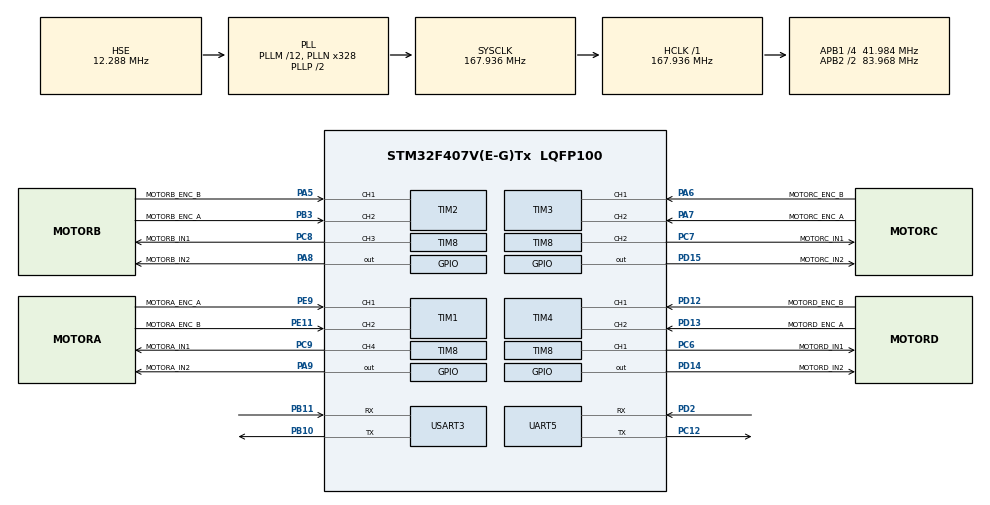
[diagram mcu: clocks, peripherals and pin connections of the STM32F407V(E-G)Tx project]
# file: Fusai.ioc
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Dma.Request0=UART5_RX
Dma.Request1=USART3_RX
Dma.UART5_RX.0.Direction=DMA_PERIPH_TO_MEMORY
Dma.UART5_RX.0.FIFOMode=DMA_FIFOMODE_DISABLE
Dma.UART5_RX.0.Instance=DMA1_Stream0
Dma.UART5_RX.0.MemDataAlignment=DMA_MDATAALIGN_BYTE
Dma.UART5_RX.0.MemInc=DMA_MINC_ENABLE
Dma.UART5_RX.0.Mode=DMA_CIRCULAR
Dma.UART5_RX.0.PeriphDataAlignment=DMA_PDATAALIGN_BYTE
Dma.UART5_RX.0.PeriphInc=DMA_PINC_DISABLE
Dma.UART5_RX.0.Priority=DMA_PRIORITY_MEDIUM
Dma.USART3_RX.1.Direction=DMA_PERIPH_TO_MEMORY
Dma.USART3_RX.1.FIFOMode=DMA_FIFOMODE_DISABLE
Dma.USART3_RX.1.Instance=DMA1_Stream1
Dma.USART3_RX.1.MemDataAlignment=DMA_MDATAALIGN_BYTE
Dma.USART3_RX.1.MemInc=DMA_MINC_ENABLE
Dma.USART3_RX.1.Mode=DMA_CIRCULAR
Dma.USART3_RX.1.PeriphDataAlignment=DMA_PDATAALIGN_BYTE
Dma.USART3_RX.1.PeriphInc=DMA_PINC_DISABLE
Dma.USART3_RX.1.Priority=DMA_PRIORITY_MEDIUM
FREERTOS.Tasks01=defaultTask,24,256,StartDefaultTask,As weak,NULL,Dynamic,NULL,NULL
FREERTOS.configCHECK_FOR_STACK_OVERFLOW=2
FREERTOS.configENABLE_FPU=1
FREERTOS.configMINIMAL_STACK_SIZE=256
Mcu.Family=STM32F4
Mcu.Name=STM32F407V(E-G)Tx
Mcu.Package=LQFP100
NVIC.DMA1_Stream0_IRQn=true\:5\:0\:false\:false\:true\:true\:false\:true\:true
NVIC.DMA1_Stream1_IRQn=true\:5\:0\:false\:false\:true\:true\:false\:true\:true
NVIC.PriorityGroup=NVIC_PRIORITYGROUP_4
NVIC.TIM1_UP_TIM10_IRQn=true\:5\:0\:true\:false\:true\:true\:true\:true\:true
NVIC.TIM8_TRG_COM_TIM14_IRQn=true\:15\:0\:false\:false\:true\:false\:false\:true\:true
NVIC.TimeBase=TIM8_TRG_COM_TIM14_IRQn
NVIC.TimeBaseIP=TIM14
NVIC.UART5_IRQn=true\:5\:0\:false\:false\:true\:true\:true\:true\:true
NVIC.USART3_IRQn=true\:5\:0\:false\:false\:true\:true\:true\:true\:true
PA13.Mode=Serial_Wire
PA13.Signal=SYS_JTMS-SWDIO
PA14.Mode=Serial_Wire
PA14.Signal=SYS_JTCK-SWCLK
PA5.GPIO_Label=MOTORB_ENC_B
PA5.GPIO_Speed=GPIO_SPEED_FREQ_HIGH
PA5.Signal=S_TIM2_CH1_ETR
PA6.GPIO_Label=MOTORC_ENC_B
PA6.GPIO_Speed=GPIO_SPEED_FREQ_HIGH
PA6.Signal=S_TIM3_CH1
PA7.GPIO_Label=MOTORC_ENC_A
PA7.GPIO_Speed=GPIO_SPEED_FREQ_HIGH
PA7.Signal=S_TIM3_CH2
PA8.GPIO_Label=MOTORB_IN2
PA8.GPIO_Speed=GPIO_SPEED_FREQ_HIGH
PA8.Signal=GPIO_Output
PA9.GPIO_Label=MOTORA_IN2
PA9.GPIO_Speed=GPIO_SPEED_FREQ_HIGH
PA9.Signal=GPIO_Output
PB10.Mode=Asynchronous
PB10.Signal=USART3_TX
PB11.Mode=Asynchronous
PB11.Signal=USART3_RX
PB3.GPIO_Label=MOTORB_ENC_A
PB3.GPIO_Speed=GPIO_SPEED_FREQ_HIGH
PB3.Signal=S_TIM2_CH2
PC12.Mode=Asynchronous
PC12.Signal=UART5_TX
PC6.GPIO_Label=MOTORD_IN1
PC6.GPIO_Speed=GPIO_SPEED_FREQ_HIGH
PC6.Signal=S_TIM8_CH1
PC7.GPIO_Label=MOTORC_IN1
PC7.GPIO_Speed=GPIO_SPEED_FREQ_HIGH
PC7.Signal=S_TIM8_CH2
PC8.GPIO_Label=MOTORB_IN1
PC8.GPIO_Speed=GPIO_SPEED_FREQ_HIGH
PC8.Signal=S_TIM8_CH3
PC9.GPIO_Label=MOTORA_IN1
PC9.GPIO_Speed=GPIO_SPEED_FREQ_HIGH
PC9.Signal=S_TIM8_CH4
PD12.GPIO_Label=MOTORD_ENC_B
PD12.GPIO_Speed=GPIO_SPEED_FREQ_HIGH
PD12.Signal=S_TIM4_CH1
PD13.GPIO_Label=MOTORD_ENC_A
PD13.GPIO_Speed=GPIO_SPEED_FREQ_HIGH
PD13.Signal=S_TIM4_CH2
PD14.GPIO_Label=MOTORD_IN2
PD14.GPIO_Speed=GPIO_SPEED_FREQ_HIGH
PD14.Signal=GPIO_Output
PD15.GPIO_Label=MOTORC_IN2
PD15.GPIO_Speed=GPIO_SPEED_FREQ_HIGH
PD15.Signal=GPIO_Output
PD2.Mode=Asynchronous
PD2.Signal=UART5_RX
PE11.GPIO_Label=MOTORA_ENC_B
PE11.GPIO_Speed=GPIO_SPEED_FREQ_HIGH
PE11.Signal=S_TIM1_CH2
PE9.GPIO_Label=MOTORA_ENC_A
PE9.GPIO_Speed=GPIO_SPEED_FREQ_HIGH
PE9.Signal=S_TIM1_CH1
PH0-OSC_IN.Mode=HSE-External-Oscillator
PH0-OSC_IN.Signal=RCC_OSC_IN
PH1-OSC_OUT.Mode=HSE-External-Oscillator
PH1-OSC_OUT.Signal=RCC_OSC_OUT
ProjectManager.HeapSize=0x200
ProjectManager.StackSize=0x400
ProjectManager.TargetToolchain=CMake
RCC.48MHZClocksFreq_Value=83968000
RCC.AHBFreq_Value=167936000
RCC.APB1CLKDivider=RCC_HCLK_DIV4
RCC.APB1Freq_Value=41984000
RCC.APB1TimFreq_Value=83968000
RCC.APB2CLKDivider=RCC_HCLK_DIV2
RCC.APB2Freq_Value=83968000
RCC.APB2TimFreq_Value=167936000
RCC.CortexFreq_Value=167936000
RCC.HCLKFreq_Value=167936000
RCC.HSE_VALUE=12288000
RCC.HSI_VALUE=16000000
RCC.LSE_VALUE=32768
RCC.PLLM=12
RCC.PLLN=328
RCC.PLLSourceVirtual=RCC_PLLSOURCE_HSE
RCC.SYSCLKFreq_VALUE=167936000
RCC.SYSCLKSource=RCC_SYSCLKSOURCE_PLLCLK
RCC.VCOOutputFreq_Value=335872000
SH.S_TIM1_CH1.0=TIM1_CH1,Encoder_Interface
SH.S_TIM1_CH2.0=TIM1_CH2,Encoder_Interface
SH.S_TIM2_CH1_ETR.0=TIM2_CH1,Encoder_Interface
SH.S_TIM2_CH2.0=TIM2_CH2,Encoder_Interface
SH.S_TIM3_CH1.0=TIM3_CH1,Encoder_Interface
SH.S_TIM3_CH2.0=TIM3_CH2,Encoder_Interface
SH.S_TIM4_CH1.0=TIM4_CH1,Encoder_Interface
SH.S_TIM4_CH2.0=TIM4_CH2,Encoder_Interface
SH.S_TIM8_CH1.0=TIM8_CH1,PWM Generation1 CH1
SH.S_TIM8_CH2.0=TIM8_CH2,PWM Generation2 CH2
SH.S_TIM8_CH3.0=TIM8_CH3,PWM Generation3 CH3
SH.S_TIM8_CH4.0=TIM8_CH4,PWM Generation4 CH4
TIM1.EncoderMode=TIM_ENCODERMODE_TI12
TIM1.IC1Filter=2
TIM1.IC2Filter=2
TIM10.Period=20000-1
TIM10.Prescaler=84-1
TIM2.EncoderMode=TIM_ENCODERMODE_TI12
TIM2.IC1Filter=2
TIM2.IC2Filter=2
TIM3.EncoderMode=TIM_ENCODERMODE_TI12
TIM3.IC1Filter=2
TIM3.IC2Filter=2
TIM4.EncoderMode=TIM_ENCODERMODE_TI12
TIM4.IC1Filter=2
TIM4.IC2Filter=2
TIM8.AutoReloadPreload=TIM_AUTORELOAD_PRELOAD_ENABLE
TIM8.Channel-PWM\ Generation1\ CH1=TIM_CHANNEL_1
TIM8.Channel-PWM\ Generation2\ CH2=TIM_CHANNEL_2
TIM8.Channel-PWM\ Generation3\ CH3=TIM_CHANNEL_3
TIM8.Channel-PWM\ Generation4\ CH4=TIM_CHANNEL_4
TIM8.Period=8400-1
TIM8.Prescaler=0
UART5.VirtualMode=Asynchronous
USART3.VirtualMode=VM_ASYNC
VP_FREERTOS_VS_CMSIS_V2.Mode=CMSIS_V2
VP_SYS_VS_tim14.Mode=TIM14
VP_TIM10_VS_ClockSourceINT.Mode=Enable_Timer
VP_TIM8_VS_ClockSourceINT.Mode=Internal
board=custom

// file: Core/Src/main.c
/* USER CODE BEGIN Header */
/**
 ******************************************************************************
 * @file           : main.c
 * @brief          : Main program body
 ******************************************************************************
 * @attention
 *
 * Copyright (c) 2026 STMicroelectronics.
 * All rights reserved.
 *
 * This software is licensed under terms that can be found in the LICENSE file
 * in the root directory of this software component.
 * If no LICENSE file comes with this software, it is provided AS-IS.
 *
 ******************************************************************************
 */
/* USER CODE END Header */
#include "main.h"
#include "cmsis_os.h"

/* USER CODE BEGIN Includes */
#include "motor.h"
/* USER CODE END Includes */

TIM_HandleTypeDef htim1;
TIM_HandleTypeDef htim2;
TIM_HandleTypeDef htim3;
TIM_HandleTypeDef htim4;
TIM_HandleTypeDef htim8;
TIM_HandleTypeDef htim10;

UART_HandleTypeDef huart5;
UART_HandleTypeDef huart3;
DMA_HandleTypeDef hdma_uart5_rx;
DMA_HandleTypeDef hdma_usart3_rx;

/* Definitions for defaultTask */
osThreadId_t defaultTaskHandle;
const osThreadAttr_t defaultTask_attributes = {
  .name = "defaultTask",
  .stack_size = 256 * 4,
  .priority = (osPriority_t) osPriorityNormal,
};

void SystemClock_Config(void);
static void MX_GPIO_Init(void);
static void MX_DMA_Init(void);
static void MX_TIM1_Init(void);
static void MX_TIM2_Init(void);
static void MX_TIM3_Init(void);
static void MX_TIM4_Init(void);
static void MX_TIM8_Init(void);
static void MX_TIM10_Init(void);
static void MX_UART5_Init(void);
static void MX_USART3_UART_Init(void);
void StartDefaultTask(void *argument);

int main(void)
{

  /* MCU Configuration--------------------------------------------------------*/

  /* Reset of all peripherals, Initializes the Flash interface and the Systick. */
  HAL_Init();

  /* Configure the system clock */
  SystemClock_Config();

  /* Initialize all configured peripherals */
  MX_GPIO_Init();
  MX_DMA_Init();
  MX_TIM1_Init();
  MX_TIM2_Init();
  MX_TIM3_Init();
  MX_TIM4_Init();
  MX_TIM8_Init();
  MX_TIM10_Init();
  MX_UART5_Init();
  MX_USART3_UART_Init();

  /* Init scheduler */
  osKernelInitialize();

  /* Create the thread(s) */
  /* creation of defaultTask */
  defaultTaskHandle = osThreadNew(StartDefaultTask, NULL, &defaultTask_attributes);

  /* Start scheduler */
  osKernelStart();

  /* We should never get here as control is now taken by the scheduler */

  /* Infinite loop */
	while (1)
	{

	}
}

void SystemClock_Config(void)
{
  RCC_OscInitTypeDef RCC_OscInitStruct = {0};
  RCC_ClkInitTypeDef RCC_ClkInitStruct = {0};

  /** Configure the main internal regulator output voltage
  */
  __HAL_RCC_PWR_CLK_ENABLE();
  __HAL_PWR_VOLTAGESCALING_CONFIG(PWR_REGULATOR_VOLTAGE_SCALE1);

  /** Initializes the RCC Oscillators according to the specified parameters
  * in the RCC_OscInitTypeDef structure.
  */
  RCC_OscInitStruct.OscillatorType = RCC_OSCILLATORTYPE_HSE;
  RCC_OscInitStruct.HSEState = RCC_HSE_ON;
  RCC_OscInitStruct.PLL.PLLState = RCC_PLL_ON;
  RCC_OscInitStruct.PLL.PLLSource = RCC_PLLSOURCE_HSE;
  RCC_OscInitStruct.PLL.PLLM = 12;
  RCC_OscInitStruct.PLL.PLLN = 328;
  RCC_OscInitStruct.PLL.PLLP = RCC_PLLP_DIV2;
  RCC_OscInitStruct.PLL.PLLQ = 4;
  if (HAL_RCC_OscConfig(&RCC_OscInitStruct) != HAL_OK)
  {
    Error_Handler();
  }

  /** Initializes the CPU, AHB and APB buses clocks
  */
  RCC_ClkInitStruct.ClockType = RCC_CLOCKTYPE_HCLK|RCC_CLOCKTYPE_SYSCLK
                              |RCC_CLOCKTYPE_PCLK1|RCC_CLOCKTYPE_PCLK2;
  RCC_ClkInitStruct.SYSCLKSource = RCC_SYSCLKSOURCE_PLLCLK;
  RCC_ClkInitStruct.AHBCLKDivider = RCC_SYSCLK_DIV1;
  RCC_ClkInitStruct.APB1CLKDivider = RCC_HCLK_DIV4;
  RCC_ClkInitStruct.APB2CLKDivider = RCC_HCLK_DIV2;

  if (HAL_RCC_ClockConfig(&RCC_ClkInitStruct, FLASH_LATENCY_5) != HAL_OK)
  {
    Error_Handler();
  }
}

static void MX_TIM1_Init(void)
{

  TIM_Encoder_InitTypeDef sConfig = {0};
  TIM_MasterConfigTypeDef sMasterConfig = {0};

  htim1.Instance = TIM1;
  htim1.Init.Prescaler = 0;
  htim1.Init.CounterMode = TIM_COUNTERMODE_UP;
  htim1.Init.Period = 65535;
  htim1.Init.ClockDivision = TIM_CLOCKDIVISION_DIV1;
  htim1.Init.RepetitionCounter = 0;
  htim1.Init.AutoReloadPreload = TIM_AUTORELOAD_PRELOAD_DISABLE;
  sConfig.EncoderMode = TIM_ENCODERMODE_TI12;
  sConfig.IC1Polarity = TIM_ICPOLARITY_RISING;
  sConfig.IC1Selection = TIM_ICSELECTION_DIRECTTI;
  sConfig.IC1Prescaler = TIM_ICPSC_DIV1;
  sConfig.IC1Filter = 2;
  sConfig.IC2Polarity = TIM_ICPOLARITY_RISING;
  sConfig.IC2Selection = TIM_ICSELECTION_DIRECTTI;
  sConfig.IC2Prescaler = TIM_ICPSC_DIV1;
  sConfig.IC2Filter = 2;
  if (HAL_TIM_Encoder_Init(&htim1, &sConfig) != HAL_OK)
  {
    Error_Handler();
  }
  sMasterConfig.MasterOutputTrigger = TIM_TRGO_RESET;
  sMasterConfig.MasterSlaveMode = TIM_MASTERSLAVEMODE_DISABLE;
  if (HAL_TIMEx_MasterConfigSynchronization(&htim1, &sMasterConfig) != HAL_OK)
  {
    Error_Handler();
  }

}

static void MX_TIM2_Init(void)
{

  TIM_Encoder_InitTypeDef sConfig = {0};
  TIM_MasterConfigTypeDef sMasterConfig = {0};

  htim2.Instance = TIM2;
  htim2.Init.Prescaler = 0;
  htim2.Init.CounterMode = TIM_COUNTERMODE_UP;
  htim2.Init.Period = 4294967295;
  htim2.Init.ClockDivision = TIM_CLOCKDIVISION_DIV1;
  htim2.Init.AutoReloadPreload = TIM_AUTORELOAD_PRELOAD_DISABLE;
  sConfig.EncoderMode = TIM_ENCODERMODE_TI12;
  sConfig.IC1Polarity = TIM_ICPOLARITY_RISING;
  sConfig.IC1Selection = TIM_ICSELECTION_DIRECTTI;
  sConfig.IC1Prescaler = TIM_ICPSC_DIV1;
  sConfig.IC1Filter = 2;
  sConfig.IC2Polarity = TIM_ICPOLARITY_RISING;
  sConfig.IC2Selection = TIM_ICSELECTION_DIRECTTI;
  sConfig.IC2Prescaler = TIM_ICPSC_DIV1;
  sConfig.IC2Filter = 2;
  if (HAL_TIM_Encoder_Init(&htim2, &sConfig) != HAL_OK)
  {
    Error_Handler();
  }
  sMasterConfig.MasterOutputTrigger = TIM_TRGO_RESET;
  sMasterConfig.MasterSlaveMode = TIM_MASTERSLAVEMODE_DISABLE;
  if (HAL_TIMEx_MasterConfigSynchronization(&htim2, &sMasterConfig) != HAL_OK)
  {
    Error_Handler();
  }

}

static void MX_TIM3_Init(void)
{

  TIM_Encoder_InitTypeDef sConfig = {0};
  TIM_MasterConfigTypeDef sMasterConfig = {0};

  htim3.Instance = TIM3;
  htim3.Init.Prescaler = 0;
  htim3.Init.CounterMode = TIM_COUNTERMODE_UP;
  htim3.Init.Period = 65535;
  htim3.Init.ClockDivision = TIM_CLOCKDIVISION_DIV1;
  htim3.Init.AutoReloadPreload = TIM_AUTORELOAD_PRELOAD_DISABLE;
  sConfig.EncoderMode = TIM_ENCODERMODE_TI12;
  sConfig.IC1Polarity = TIM_ICPOLARITY_RISING;
  sConfig.IC1Selection = TIM_ICSELECTION_DIRECTTI;
  sConfig.IC1Prescaler = TIM_ICPSC_DIV1;
  sConfig.IC1Filter = 2;
  sConfig.IC2Polarity = TIM_ICPOLARITY_RISING;
  sConfig.IC2Selection = TIM_ICSELECTION_DIRECTTI;
  sConfig.IC2Prescaler = TIM_ICPSC_DIV1;
  sConfig.IC2Filter = 2;
  if (HAL_TIM_Encoder_Init(&htim3, &sConfig) != HAL_OK)
  {
    Error_Handler();
  }
  sMasterConfig.MasterOutputTrigger = TIM_TRGO_RESET;
  sMasterConfig.MasterSlaveMode = TIM_MASTERSLAVEMODE_DISABLE;
  if (HAL_TIMEx_MasterConfigSynchronization(&htim3, &sMasterConfig) != HAL_OK)
  {
    Error_Handler();
  }

}

static void MX_TIM4_Init(void)
{

  TIM_Encoder_InitTypeDef sConfig = {0};
  TIM_MasterConfigTypeDef sMasterConfig = {0};

  htim4.Instance = TIM4;
  htim4.Init.Prescaler = 0;
  htim4.Init.CounterMode = TIM_COUNTERMODE_UP;
  htim4.Init.Period = 65535;
  htim4.Init.ClockDivision = TIM_CLOCKDIVISION_DIV1;
  htim4.Init.AutoReloadPreload = TIM_AUTORELOAD_PRELOAD_DISABLE;
  sConfig.EncoderMode = TIM_ENCODERMODE_TI12;
  sConfig.IC1Polarity = TIM_ICPOLARITY_RISING;
  sConfig.IC1Selection = TIM_ICSELECTION_DIRECTTI;
  sConfig.IC1Prescaler = TIM_ICPSC_DIV1;
  sConfig.IC1Filter = 2;
  sConfig.IC2Polarity = TIM_ICPOLARITY_RISING;
  sConfig.IC2Selection = TIM_ICSELECTION_DIRECTTI;
  sConfig.IC2Prescaler = TIM_ICPSC_DIV1;
  sConfig.IC2Filter = 2;
  if (HAL_TIM_Encoder_Init(&htim4, &sConfig) != HAL_OK)
  {
    Error_Handler();
  }
  sMasterConfig.MasterOutputTrigger = TIM_TRGO_RESET;
  sMasterConfig.MasterSlaveMode = TIM_MASTERSLAVEMODE_DISABLE;
  if (HAL_TIMEx_MasterConfigSynchronization(&htim4, &sMasterConfig) != HAL_OK)
  {
    Error_Handler();
  }

}

static void MX_TIM8_Init(void)
{

  TIM_ClockConfigTypeDef sClockSourceConfig = {0};
  TIM_MasterConfigTypeDef sMasterConfig = {0};
  TIM_OC_InitTypeDef sConfigOC = {0};
  TIM_BreakDeadTimeConfigTypeDef sBreakDeadTimeConfig = {0};

  htim8.Instance = TIM8;
  htim8.Init.Prescaler = 0;
  htim8.Init.CounterMode = TIM_COUNTERMODE_UP;
  htim8.Init.Period = 8400-1;
  htim8.Init.ClockDivision = TIM_CLOCKDIVISION_DIV1;
  htim8.Init.RepetitionCounter = 0;
  htim8.Init.AutoReloadPreload = TIM_AUTORELOAD_PRELOAD_ENABLE;
  if (HAL_TIM_Base_Init(&htim8) != HAL_OK)
  {
    Error_Handler();
  }
  sClockSourceConfig.ClockSource = TIM_CLOCKSOURCE_INTERNAL;
  if (HAL_TIM_ConfigClockSource(&htim8, &sClockSourceConfig) != HAL_OK)
  {
    Error_Handler();
  }
  if (HAL_TIM_PWM_Init(&htim8) != HAL_OK)
  {
    Error_Handler();
  }
  sMasterConfig.MasterOutputTrigger = TIM_TRGO_RESET;
  sMasterConfig.MasterSlaveMode = TIM_MASTERSLAVEMODE_DISABLE;
  if (HAL_TIMEx_MasterConfigSynchronization(&htim8, &sMasterConfig) != HAL_OK)
  {
    Error_Handler();
  }
  sConfigOC.OCMode = TIM_OCMODE_PWM1;
  sConfigOC.Pulse = 0;
  sConfigOC.OCPolarity = TIM_OCPOLARITY_HIGH;
  sConfigOC.OCNPolarity = TIM_OCNPOLARITY_HIGH;
  sConfigOC.OCFastMode = TIM_OCFAST_DISABLE;
  sConfigOC.OCIdleState = TIM_OCIDLESTATE_RESET;
  sConfigOC.OCNIdleState = TIM_OCNIDLESTATE_RESET;
  if (HAL_TIM_PWM_ConfigChannel(&htim8, &sConfigOC, TIM_CHANNEL_1) != HAL_OK)
  {
    Error_Handler();
  }
  if (HAL_TIM_PWM_ConfigChannel(&htim8, &sConfigOC, TIM_CHANNEL_2) != HAL_OK)
  {
    Error_Handler();
  }
  if (HAL_TIM_PWM_ConfigChannel(&htim8, &sConfigOC, TIM_CHANNEL_3) != HAL_OK)
  {
    Error_Handler();
  }
  if (HAL_TIM_PWM_ConfigChannel(&htim8, &sConfigOC, TIM_CHANNEL_4) != HAL_OK)
  {
    Error_Handler();
  }
  sBreakDeadTimeConfig.OffStateRunMode = TIM_OSSR_DISABLE;
  sBreakDeadTimeConfig.OffStateIDLEMode = TIM_OSSI_DISABLE;
  sBreakDeadTimeConfig.LockLevel = TIM_LOCKLEVEL_OFF;
  sBreakDeadTimeConfig.DeadTime = 0;
  sBreakDeadTimeConfig.BreakState = TIM_BREAK_DISABLE;
  sBreakDeadTimeConfig.BreakPolarity = TIM_BREAKPOLARITY_HIGH;
  sBreakDeadTimeConfig.AutomaticOutput = TIM_AUTOMATICOUTPUT_DISABLE;
  if (HAL_TIMEx_ConfigBreakDeadTime(&htim8, &sBreakDeadTimeConfig) != HAL_OK)
  {
    Error_Handler();
  }
  HAL_TIM_MspPostInit(&htim8);

}

static void MX_TIM10_Init(void)
{

  htim10.Instance = TIM10;
  htim10.Init.Prescaler = 84-1;
  htim10.Init.CounterMode = TIM_COUNTERMODE_UP;
  htim10.Init.Period = 20000-1;
  htim10.Init.ClockDivision = TIM_CLOCKDIVISION_DIV1;
  htim10.Init.AutoReloadPreload = TIM_AUTORELOAD_PRELOAD_DISABLE;
  if (HAL_TIM_Base_Init(&htim10) != HAL_OK)
  {
    Error_Handler();
  }

}

static void MX_UART5_Init(void)
{

  huart5.Instance = UART5;
  huart5.Init.BaudRate = 115200;
  huart5.Init.WordLength = UART_WORDLENGTH_8B;
  huart5.Init.StopBits = UART_STOPBITS_1;
  huart5.Init.Parity = UART_PARITY_NONE;
  huart5.Init.Mode = UART_MODE_TX_RX;
  huart5.Init.HwFlowCtl = UART_HWCONTROL_NONE;
  huart5.Init.OverSampling = UART_OVERSAMPLING_16;
  if (HAL_UART_Init(&huart5) != HAL_OK)
  {
    Error_Handler();
  }

}

static void MX_USART3_UART_Init(void)
{

  huart3.Instance = USART3;
  huart3.Init.BaudRate = 115200;
  huart3.Init.WordLength = UART_WORDLENGTH_8B;
  huart3.Init.StopBits = UART_STOPBITS_1;
  huart3.Init.Parity = UART_PARITY_NONE;
  huart3.Init.Mode = UART_MODE_TX_RX;
  huart3.Init.HwFlowCtl = UART_HWCONTROL_NONE;
  huart3.Init.OverSampling = UART_OVERSAMPLING_16;
  if (HAL_UART_Init(&huart3) != HAL_OK)
  {
    Error_Handler();
  }

}

static void MX_DMA_Init(void)
{

  /* DMA controller clock enable */
  __HAL_RCC_DMA1_CLK_ENABLE();

  /* DMA interrupt init */
  /* DMA1_Stream0_IRQn interrupt configuration */
  HAL_NVIC_SetPriority(DMA1_Stream0_IRQn, 5, 0);
  HAL_NVIC_EnableIRQ(DMA1_Stream0_IRQn);
  /* DMA1_Stream1_IRQn interrupt configuration */
  HAL_NVIC_SetPriority(DMA1_Stream1_IRQn, 5, 0);
  HAL_NVIC_EnableIRQ(DMA1_Stream1_IRQn);

}

static void MX_GPIO_Init(void)
{
  GPIO_InitTypeDef GPIO_InitStruct = {0};

  /* GPIO Ports Clock Enable */
  __HAL_RCC_GPIOH_CLK_ENABLE();
  __HAL_RCC_GPIOA_CLK_ENABLE();
  __HAL_RCC_GPIOE_CLK_ENABLE();
  __HAL_RCC_GPIOB_CLK_ENABLE();
  __HAL_RCC_GPIOD_CLK_ENABLE();
  __HAL_RCC_GPIOC_CLK_ENABLE();

  /*Configure GPIO pin Output Level */
  HAL_GPIO_WritePin(GPIOD, MOTORD_IN2_Pin|MOTORC_IN2_Pin, GPIO_PIN_RESET);

  /*Configure GPIO pin Output Level */
  HAL_GPIO_WritePin(GPIOA, MOTORB_IN2_Pin|MOTORA_IN2_Pin, GPIO_PIN_RESET);

  /*Configure GPIO pins : MOTORD_IN2_Pin MOTORC_IN2_Pin */
  GPIO_InitStruct.Pin = MOTORD_IN2_Pin|MOTORC_IN2_Pin;
  GPIO_InitStruct.Mode = GPIO_MODE_OUTPUT_PP;
  GPIO_InitStruct.Pull = GPIO_NOPULL;
  GPIO_InitStruct.Speed = GPIO_SPEED_FREQ_HIGH;
  HAL_GPIO_Init(GPIOD, &GPIO_InitStruct);

  /*Configure GPIO pins : MOTORB_IN2_Pin MOTORA_IN2_Pin */
  GPIO_InitStruct.Pin = MOTORB_IN2_Pin|MOTORA_IN2_Pin;
  GPIO_InitStruct.Mode = GPIO_MODE_OUTPUT_PP;
  GPIO_InitStruct.Pull = GPIO_NOPULL;
  GPIO_InitStruct.Speed = GPIO_SPEED_FREQ_HIGH;
  HAL_GPIO_Init(GPIOA, &GPIO_InitStruct);

}

__weak void StartDefaultTask(void *argument)
{
}

void HAL_TIM_PeriodElapsedCallback(TIM_HandleTypeDef *htim)
{
  /* USER CODE BEGIN Callback 0 */
	if (htim->Instance == TIM10)
	{
		Motor_10ms_Tick();
	}
  /* USER CODE END Callback 0 */
  if (htim->Instance == TIM14)
  {
    HAL_IncTick();
  }
}

void Error_Handler(void)
{
	__disable_irq();
	while (1)
	{
	}
}
#ifdef USE_FULL_ASSERT
/**
  * @brief  Reports the name of the source file and the source line number
  *         where the assert_param error has occurred.
  * @param  file: pointer to the source file name
  * @param  line: assert_param error line source number
  * @retval None
  */
void assert_failed(uint8_t *file, uint32_t line)
{
  /* USER CODE BEGIN 6 */
	/* User can add his own implementation to report the file name and line
	   number, ex: printf("Wrong parameters value: file %s on line %d\r\n", file,
	   line) */
  /* USER CODE END 6 */
}
#endif /* USE_FULL_ASSERT */
